# max32570 register map
Vendor: Maxim-Integrated; Series: ARMCM4; File version: 1.0
CPU: CM4 r2p1, little endian, MPU, FPU, 3 interrupt priority bits
Registers are 32-bit, read-write, reset 0x0 unless marked. A register's access mark holds for its fields unless they carry their own. Offsets are from the block's base; [hi:lo] are bit positions; {n}, {i} and the like mark numbered series.

## FCR — Function Control Register.
Base 0x40000800
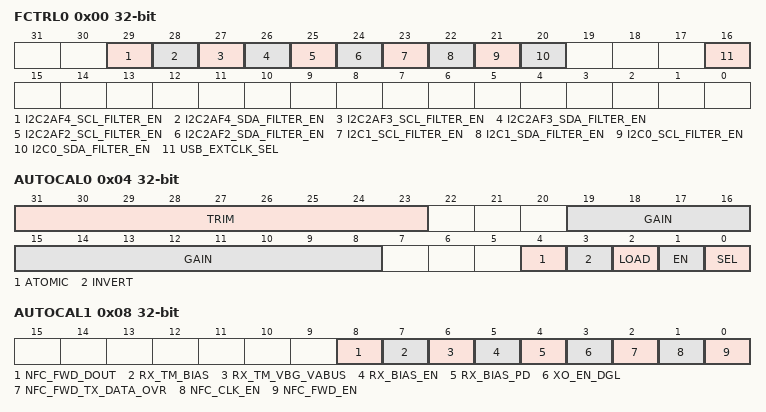
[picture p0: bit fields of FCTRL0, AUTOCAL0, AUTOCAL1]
0x00 FCTRL0 — Register 0.
  [29] I2C2AF4_SCL_FILTER_EN — I2C2 AF4 SCL Glitch Filter Enable
    0=dis (Filter disabled.); 1=en (Filter enabled.)
  [28] I2C2AF4_SDA_FILTER_EN — I2C2 AF4 SDA Glitch Filter Enable
    0=dis (Filter disabled.); 1=en (Filter enabled.)
  [27] I2C2AF3_SCL_FILTER_EN — I2C2 AF3 SCL Glitch Filter Enable.
    0=dis (Filter disabled.); 1=en (Filter enabled.)
  [26] I2C2AF3_SDA_FILTER_EN — I2C2 AF3 SDA Glitch Filter Enable.
    0=dis (Filter disabled.); 1=en (Filter enabled.)
  [25] I2C2AF2_SCL_FILTER_EN — I2C2 AF2 SCL Glitch Filter Enable.
    0=dis (Filter disabled.); 1=en (Filter enabled.)
  [24] I2C2AF2_SDA_FILTER_EN — I2C2 AF2 SDA Glitch Filter Enable.
    0=dis (Filter disabled.); 1=en (Filter enabled.)
  [23] I2C1_SCL_FILTER_EN — I2C1 SCL Glitch Filter Enable.
    0=dis (Filter disabled.); 1=en (Filter enabled.)
  [22] I2C1_SDA_FILTER_EN — I2C1 SDA Glitch Filter Enable.
    0=dis (Filter disabled.); 1=en (Filter enabled.)
  [21] I2C0_SCL_FILTER_EN — I2C0 SCL Glitch Filter Enable.
    0=dis (Filter disabled.); 1=en (Filter enabled.)
  [20] I2C0_SDA_FILTER_EN — I2C0 SDA Glitch Filter Enable.
    0=dis (Filter disabled.); 1=en (Filter enabled.)
  [16] USB_EXTCLK_SEL — USB External Core Clock Select.
    0=sys (Generated clock from system clock.); 1=dig (Digital clock from a GPIO.)
0x04 AUTOCAL0 — Register 1.
  [31:23] TRIM — 150MHz HFIO Auto Calibration Trim
  [19:8] GAIN — MU value.
  [4] ATOMIC — Atomic mode.
    0=not (Not Running.); 1=run (Running.)
  [3] INVERT — Invert Gain.
    0=not (Not Running.); 1=run (Running.)
  [2] LOAD — Load Trim.
  [1] EN — Autocalibration Run.
    0=not (Not Running.); 1=run (Running.)
  [0] SEL — Auto-calibration Enable.
    0=dis (Disabled.); 1=en (Enabled.)
0x08 AUTOCAL1 — Register 2.
  [8] NFC_FWD_DOUT — FWD output from FNC block
  [7] RX_TM_BIAS
  [6] RX_TM_VBG_VABUS
  [5] RX_BIAS_EN — Enable the NFC receiver analog blocks
  [4] RX_BIAS_PD — Power down enable for NFC receiver analog block
  [3] XO_EN_DGL
  [2] NFC_FWD_TX_DATA_OVR — FWD input for NFC block
  [1] NFC_CLK_EN — Enabled the NFC blocks clock divider in Analog
  [0] NFC_FWD_EN — Enabled FWD mode for NFC block
0x0C AUTOCAL2 — Register 3.
  [7:0] RUNTIME — Automatic Calibration Run Time.

## FLC — Flash Memory Control.
Base 0x40029000; register names take the prefix FLSH_
Same registers: FLC1 0x40029400
0x00 ADDR — Flash Write Address.
  [31:0] ADDR — Address for next operation.
0x04 CLKDIV reset 0x64 — Flash Clock Divide. The clock (PLL0) is divided by this value to generate a 1 MHz clock for Flash controller.
  [7:0] CLKDIV — Flash Clock Divide. The clock is divided by this value to generate a 1MHz clock for flash controller.
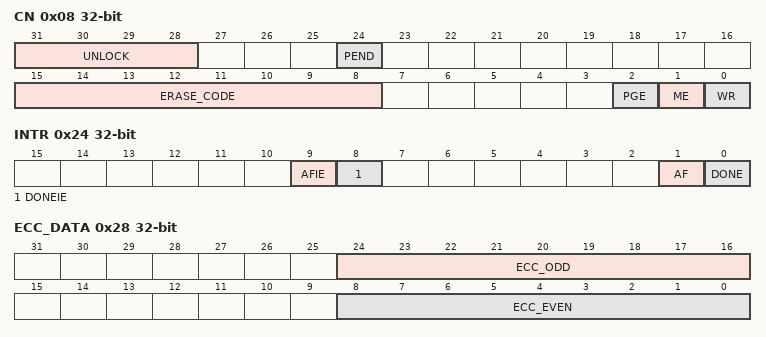
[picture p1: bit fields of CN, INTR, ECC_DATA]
0x08 CN — Flash Control Register.
  [31:28] UNLOCK — Flash Unlock. The correct unlock code must be written to these four bits before any Flash write or erase operation is allowed.
    2=unlocked (Flash Unlocked.); 3=locked (Flash Locked.)
  [24] PEND ro — Flash Pending. When Flash operation is in progress (busy), Flash reads and writes will fail. When PEND is set, write to all Flash registers, with exception of the Flash interrupt register, are ignored.
    0=idle; 1=busy
  [15:8] ERASE_CODE — Erase Code. The ERASE_CODE must be set up property before erase operation can be initiated. These bits are automatically cleared after the operation is complete.
    0=nop (No operation.); 85=erasePage (Enable Page Erase.); 170=eraseAll (Enable Mass Erase. The debug port must be enabled.)
  [2] PGE — Page Erase. This bit is automatically cleared after the operation.
    0=complete (No operation/complete.); 1=Start operation
  [1] ME — Mass Erase. This bit is automatically cleared after the operation.
    0=complete (No operation/complete.); 1=Start operation
  [0] WR — Write. This bit is automatically cleared after the operation.
    0=complete (No operation/complete.); 1=Start operation
0x24 INTR — Flash Interrupt Register.
  [9] AFIE — Flash Done Interrupt Enable.
    0=disable; 1=enable
  [8] DONEIE — Flash Done Interrupt Enable.
    0=disable; 1=enable
  [1] AF — Flash Access Fail. This bit is set when an attempt is made to write the flash while the flash is busy or the flash is locked. This bit can only be set to 1 by hardware.
    0=noError (No Failure.); 1=error (Failure occurs.)
  [0] DONE — Flash Done Interrupt. This bit is set to 1 upon Flash write or erase completion.
    0=inactive (No interrupt is pending.); 1=pending (An interrupt is pending.)
0x28 ECC_DATA
  [24:16] ECC_ODD — Error Correction Code Even Data.
  [8:0] ECC_EVEN — Error Correction Code Odd Data.
{0x30+4i} DATA[{i}] (i=0..3) — Flash Write Data.
  [31:0] DATA — Data next operation.
